AUTOSAR XML (schema 00051)
package /Components
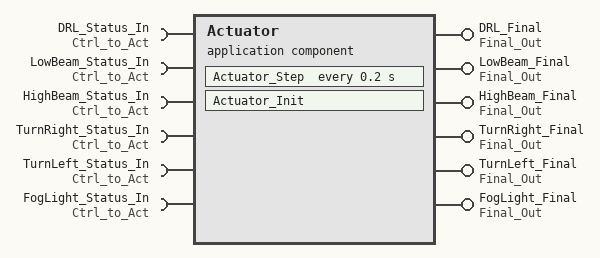
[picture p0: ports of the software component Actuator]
  application sw component type Actuator
    6 x require port, all with nonqueued-receiver-com-spec{data-element=Value, init-value=0}, required-interface=Ctrl_to_Act:
      DRL_Status_In
      LowBeam_Status_In
      HighBeam_Status_In
      TurnRight_Status_In
      TurnLeft_Status_In
      FogLight_Status_In
    6 x provide port, all with nonqueued-sender-com-spec{data-element=Value, init-value=0}, provided-interface=Final_Out:
      DRL_Final
      LowBeam_Final
      HighBeam_Final
      TurnRight_Final
      TurnLeft_Final
      FogLight_Final
    behavior Actuator_IB: handle-termination-and-restart=NO-SUPPORT
      timing event Event_Actuator_Step: start-on-event=Actuator_Step, period=0.2
      runnable Actuator_Init
      runnable Actuator_Step
        data-read-access:
          6 x access:
            IN_DRL_Status_In_Value: accessed-variable=DRL_Status_In.Value
            IN_LowBeam_Status_In_Value: accessed-variable=LowBeam_Status_In.Value
            IN_HighBeam_Status_In_Value: accessed-variable=HighBeam_Status_In.Value
            IN_TurnRight_Status_In_Value: accessed-variable=TurnRight_Status_In.Value
            IN_TurnLeft_Status_In_Value: accessed-variable=TurnLeft_Status_In.Value
            IN_FogLight_Status_In_Value: accessed-variable=FogLight_Status_In.Value
        data-write-access:
          6 x access:
            OUT_DRL_Final_Value: accessed-variable=DRL_Final.Value
            OUT_LowBeam_Final_Value: accessed-variable=LowBeam_Final.Value
            OUT_HighBeam_Final_Value: accessed-variable=HighBeam_Final.Value
            OUT_TurnRight_Final_Value: accessed-variable=TurnRight_Final.Value
            OUT_TurnLeft_Final_Value: accessed-variable=TurnLeft_Final.Value
            OUT_FogLight_Final_Value: accessed-variable=FogLight_Final.Value
